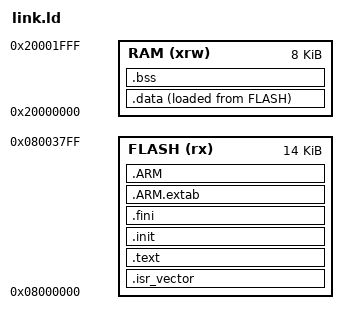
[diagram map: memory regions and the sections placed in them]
/* Bootloader: 14 KB code + 2 KB parameter page at 0x08003800. */
ENTRY(Reset_Handler)

_estack = ORIGIN(RAM) + LENGTH(RAM);

MEMORY
{
  FLASH (rx)  : ORIGIN = 0x08000000, LENGTH = 14K
  RAM   (xrw) : ORIGIN = 0x20000000, LENGTH = 8K
}

SECTIONS
{
  .isr_vector :
  {
    . = ALIGN(4);
    KEEP(*(.isr_vector))
    . = ALIGN(4);
  } >FLASH

  .text :
  {
    . = ALIGN(4);
    *(.text)
    *(.text*)
    *(.rodata)
    *(.rodata*)
    . = ALIGN(4);
  } >FLASH

  .init :
  {
    KEEP(*(.init))
  } >FLASH

  .fini :
  {
    KEEP(*(.fini))
  } >FLASH

  .ARM.extab :
  {
    *(.ARM.extab* .gnu.linkonce.armextab.*)
  } >FLASH

  .ARM :
  {
    __exidx_start = .;
    *(.ARM.exidx*)
    __exidx_end = .;
  } >FLASH

  _sidata = LOADADDR(.data);

  .data :
  {
    . = ALIGN(4);
    _sdata = .;
    *(.data)
    *(.data*)
    . = ALIGN(4);
    _edata = .;
  } >RAM AT> FLASH

  .bss :
  {
    . = ALIGN(4);
    _sbss = .;
    *(.bss)
    *(.bss*)
    *(COMMON)
    . = ALIGN(4);
    _ebss = .;
  } >RAM
}
